AUTOSAR XML (schema 00044)
package /ComponentTypes
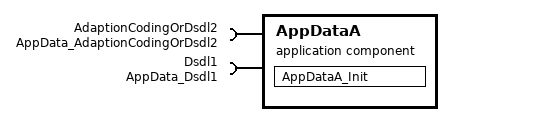
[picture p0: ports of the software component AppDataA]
  application sw component type AppDataA
    require port AdaptionCodingOrDsdl2: client-com-spec=Data, required-interface=AppData_AdaptionCodingOrDsdl2
    require port Dsdl1: required-com-specs=[AdrRange, Data], required-interface=AppData_Dsdl1
    behavior AppDataA_InternalBehavior
      init event AppDataA_InitEvent: start-on-event=AppDataA_Init
      runnable AppDataA_Init
        sync call SC_AdaptionCodingOrDsdl2_Data: operation=AdaptionCodingOrDsdl2.Data
        sync call SC_Dsdl1_AdrRange: operation=Dsdl1.AdrRange
        sync call SC_Dsdl1_Data: operation=Dsdl1.Data
  swc implementation AppDataA_Implementation: vendor-id=75, behavior=AppDataA_InternalBehavior
    code-descriptors:
      code Default: artifact-descriptors=autosar-engineering-object=category=SWSRC
    resource consumption ResourceConsumption
      memory section CODE: sw-addrmethod=CODE
